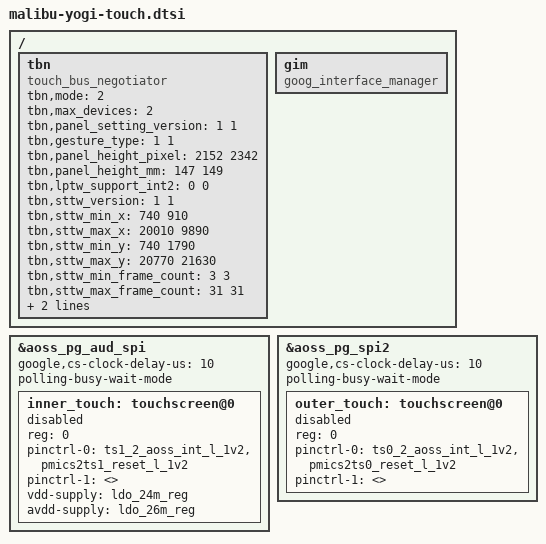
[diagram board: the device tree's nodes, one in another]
// SPDX-License-Identifier: GPL-2.0-only OR BSD-3-Clause
/*
 * yogi common touch device tree source
 *
 * Copyright 2025 Google LLC
 */

/ {
	fragment@touch_bus_negotiator {
		target-path = "/";
		__overlay__ {
			tbn: tbn {
				compatible = "touch_bus_negotiator";
				tbn,mode = <2>;
				tbn,max_devices = <2>;

				/* Panel Settings, <inner outer> */
				tbn,panel_setting_version = /bits/ 8 <1 1>;
				tbn,gesture_type = /bits/ 8 <1 1>;
				tbn,panel_height_pixel = /bits/ 16 <2152 2342>;
				tbn,panel_height_mm = /bits/ 16 <147 149>;
				tbn,lptw_support_int2 = /bits/ 8 <0 0>;

				/* STTW Configs, <inner outer> */
				tbn,sttw_version = /bits/ 8 <1 1>;
				tbn,sttw_min_x = /bits/ 16 <740 910>;
				tbn,sttw_max_x = /bits/ 16 <20010 9890>;
				tbn,sttw_min_y = /bits/ 16 <740 1790>;
				tbn,sttw_max_y = /bits/ 16 <20770 21630>;
				tbn,sttw_min_frame_count = /bits/ 8 <3 3>;
				tbn,sttw_max_frame_count = /bits/ 8 <31 31>;
				tbn,sttw_motion_tolerance = /bits/ 16 <2550 2550>;
				tbn,sttw_max_touch_size = /bits/ 8 <50 50>;
			};
		};
	};
};

/ {
	fragment@goog_interface_manager {
		target-path = "/";
		__overlay__ {
			gim: gim {
				compatible = "goog_interface_manager";
			};
		};
	};
};

/*
 * Inner touch pins:
 *
 * SSWRP_AOSS_AUD_SPI = AOSS_AMB_SPI1
 *   XAOSS_AMB_SPI1_SCLK = AOSS2TS1_SPI_CLK_1V2
 *   XAOSS_AMB_SPI1_MOSI = AOSS2TS1_SPI_MOSI_1V2
 *   XAOSS_AMB_SPI1_MISO = AOSS2TS1_SPI_MISO_1V2
 *   XAOSS_AMB_SPI1_CSn = AOSS2TS1_SPI_CS_L_1V2
 *
 * XAOSS_SC_GPIO13 = TS1_2_AOSS_INT_L_1V2
 * DA9188_SUB_GPIO_18 = PMICS2TS1_RESET_L_1V2
 *
 * DVDD = VLDO24M
 * AVDD = VLDO26M
 */

&aoss_pg_aud_spi {
	google,cs-clock-delay-us = <10>;
	polling-busy-wait-mode;

	inner_touch: touchscreen@0 {
		#address-cells = <1>;
		#size-cells = <1>;

		status = "disabled";
		reg = <0>;
		pinctrl-names = "ts_active", "ts_suspend";
		pinctrl-0 = <&ts1_2_aoss_int_l_1v2 &pmics2ts1_reset_l_1v2>; /* TODO: pinctrl */
		pinctrl-1 = <>;

		vdd-supply = <&ldo_24m_reg>;
		avdd-supply = <&ldo_26m_reg>;
	};
};

/*
 * Outer touch pins:
 *
 * SSWRP_AOSS_SPI2 = AOSS_AMB_SPI3
 *   XAOSS_AMB_SPI3_SCLK = AOSS2TS0_SPI_CLK_1V2
 *   XAOSS_AMB_SPI3_MOSI = AOSS2TS0_SPI_MOSI_1V2
 *   XAOSS_AMB_SPI3_MISO = AOSS2TS0_SPI_MISO_1V2
 *   XAOSS_AMB_SPI3_CSn = AOSS2TS0_SPI_CS_L_1V2
 *
 * XAOSS_SC_GPIO12 = TS0_2_AOSS_INT_L_1V2
 * DA9188_SUB_GPIO_17 = PMICS2TS0_RESET_L_1V2
 */

&aoss_pg_spi2 {
	google,cs-clock-delay-us = <10>;
	polling-busy-wait-mode;

	outer_touch: touchscreen@0 {
		#address-cells = <1>;
		#size-cells = <1>;

		status = "disabled";
		reg = <0>;
		pinctrl-names = "ts_active", "ts_suspend";
		pinctrl-0 = <&ts0_2_aoss_int_l_1v2 &pmics2ts0_reset_l_1v2>; /* TODO: pinctrl */
		pinctrl-1 = <>;
	};
};
